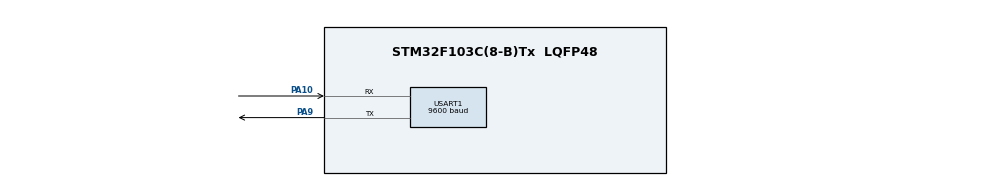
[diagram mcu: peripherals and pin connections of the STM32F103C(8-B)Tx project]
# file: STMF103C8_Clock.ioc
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Mcu.Family=STM32F1
Mcu.Name=STM32F103C(8-B)Tx
Mcu.Package=LQFP48
NVIC.PriorityGroup=NVIC_PRIORITYGROUP_4
NVIC.TIM4_IRQn=true\:15\:0\:false\:false\:true\:false\:true\:true
NVIC.TimeBase=TIM4_IRQn
NVIC.TimeBaseIP=TIM4
NVIC.USART1_IRQn=true\:6\:0\:true\:false\:true\:true\:true\:true
PA10.Mode=Asynchronous
PA10.Signal=USART1_RX
PA13.Mode=Trace_Asynchronous_SW
PA13.Signal=SYS_JTMS-SWDIO
PA14.Mode=Trace_Asynchronous_SW
PA14.Signal=SYS_JTCK-SWCLK
PA9.Mode=Asynchronous
PA9.Signal=USART1_TX
PB3.Mode=Trace_Asynchronous_SW
PB3.Signal=SYS_JTDO-TRACESWO
PC14-OSC32_IN.Mode=LSE-External-Oscillator
PC14-OSC32_IN.Signal=RCC_OSC32_IN
PC15-OSC32_OUT.Mode=LSE-External-Oscillator
PC15-OSC32_OUT.Signal=RCC_OSC32_OUT
PD0-OSC_IN.Mode=HSE-External-Oscillator
PD0-OSC_IN.Signal=RCC_OSC_IN
PD1-OSC_OUT.Mode=HSE-External-Oscillator
PD1-OSC_OUT.Signal=RCC_OSC_OUT
ProjectManager.HeapSize=0x200
ProjectManager.StackSize=0x400
ProjectManager.TargetToolchain=STM32CubeIDE
RCC.APB1Freq_Value=8000000
RCC.APB2Freq_Value=8000000
RCC.RTCClockSelection=RCC_RTCCLKSOURCE_LSE
RCC.SYSCLKSource=RCC_SYSCLKSOURCE_HSE
RTC.Format=RTC_FORMAT_BIN
USART1.BaudRate=9600
USART1.VirtualMode=VM_ASYNC
VP_RTC_VS_RTC_Activate.Mode=RTC_Enabled
VP_RTC_VS_RTC_Calendar.Mode=RTC_Calendar
VP_SYS_VS_tim4.Mode=TIM4
board=custom

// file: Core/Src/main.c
/* USER CODE BEGIN Header */
/**
  ******************************************************************************
  * @file           : main.c
  * @brief          : Main program body
  ******************************************************************************
  * @attention
  *
  * <h2><center>&copy; Copyright (c) 2021 STMicroelectronics.
  * All rights reserved.</center></h2>
  *
  * This software component is licensed by ST under BSD 3-Clause license,
  * the "License"; You may not use this file except in compliance with the
  * License. You may obtain a copy of the License at:
  *                        opensource.org/licenses/BSD-3-Clause
  *
  ******************************************************************************
  */
/* USER CODE END Header */
#include "main.h"
#include "rtc.h"
#include "usart.h"
#include "gpio.h"

/* USER CODE BEGIN Includes */
#include "FreeRTOS.h"
#include "task.h"
#include "queue.h"

#include "SEGGER_SYSVIEW.h"

#include "SchM_DigitalClock.h"
/* USER CODE END Includes */

/* USER CODE BEGIN PV */

extern RTC_HandleTypeDef hrtc;
extern UART_HandleTypeDef huart1;

/* USER CODE END PV */

void SystemClock_Config(void);

int main(void)
{

  /* MCU Configuration--------------------------------------------------------*/

  /* Reset of all peripherals, Initializes the Flash interface and the Systick. */
  HAL_Init();

  /* Configure the system clock */
  SystemClock_Config();

  /* Initialize all configured peripherals */
  MX_GPIO_Init();
  MX_RTC_Init();
  MX_USART1_UART_Init();
  SEGGER_SYSVIEW_Conf();
  SEGGER_SYSVIEW_Start();

  /* USER CODE BEGIN 2 */
  Task_Generation();

  vTaskStartScheduler();

  /* USER CODE END 2 */

  /* Infinite loop */
  while (1)
  {

  }
}

void SystemClock_Config(void)
{
  RCC_OscInitTypeDef RCC_OscInitStruct = {0};
  RCC_ClkInitTypeDef RCC_ClkInitStruct = {0};
  RCC_PeriphCLKInitTypeDef PeriphClkInit = {0};

  /** Initializes the RCC Oscillators according to the specified parameters
  * in the RCC_OscInitTypeDef structure.
  */
  RCC_OscInitStruct.OscillatorType = RCC_OSCILLATORTYPE_HSE|RCC_OSCILLATORTYPE_LSE;
  RCC_OscInitStruct.HSEState = RCC_HSE_ON;
  RCC_OscInitStruct.LSEState = RCC_LSE_ON;
  RCC_OscInitStruct.PLL.PLLState = RCC_PLL_NONE;
  if (HAL_RCC_OscConfig(&RCC_OscInitStruct) != HAL_OK)
  {
    Error_Handler();
  }

  /** Initializes the CPU, AHB and APB buses clocks
  */
  RCC_ClkInitStruct.ClockType = RCC_CLOCKTYPE_HCLK|RCC_CLOCKTYPE_SYSCLK
                              |RCC_CLOCKTYPE_PCLK1|RCC_CLOCKTYPE_PCLK2;
  RCC_ClkInitStruct.SYSCLKSource = RCC_SYSCLKSOURCE_HSE;
  RCC_ClkInitStruct.AHBCLKDivider = RCC_SYSCLK_DIV1;
  RCC_ClkInitStruct.APB1CLKDivider = RCC_HCLK_DIV1;
  RCC_ClkInitStruct.APB2CLKDivider = RCC_HCLK_DIV1;

  if (HAL_RCC_ClockConfig(&RCC_ClkInitStruct, FLASH_LATENCY_0) != HAL_OK)
  {
    Error_Handler();
  }
  PeriphClkInit.PeriphClockSelection = RCC_PERIPHCLK_RTC;
  PeriphClkInit.RTCClockSelection = RCC_RTCCLKSOURCE_LSE;
  if (HAL_RCCEx_PeriphCLKConfig(&PeriphClkInit) != HAL_OK)
  {
    Error_Handler();
  }
}

/* USER CODE BEGIN 4 */

#if Debug_ITM
int _write(int file, char *ptr, int len)
{
	int DataIdx;

	for (DataIdx = 0; DataIdx < len; DataIdx++)
	{
		ITM_SendChar(*ptr++);
	}
	return len;
}
#endif

void HAL_UART_TxCpltCallback(UART_HandleTypeDef *huart)
{
   __NOP();// do nothing here
}

void HAL_UART_RxCpltCallback(UART_HandleTypeDef *huart)
{
	__NOP();// do nothing here
}
/* USER CODE END 4 */

void HAL_TIM_PeriodElapsedCallback(TIM_HandleTypeDef *htim)
{
  if (htim->Instance == TIM4) {
    HAL_IncTick();
  }
}

void Error_Handler(void)
{
  __disable_irq();
  while (1)
  {
  }
}
